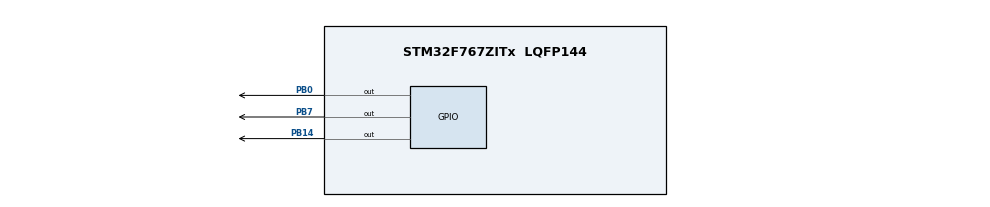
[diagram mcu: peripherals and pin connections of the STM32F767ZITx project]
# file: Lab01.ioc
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Mcu.Family=STM32F7
Mcu.Name=STM32F767ZITx
Mcu.Package=LQFP144
NVIC.PriorityGroup=NVIC_PRIORITYGROUP_4
PB0.Signal=GPIO_Output
PB14.Signal=GPIO_Output
PB7.Signal=GPIO_Output
ProjectManager.HeapSize=0x200
ProjectManager.StackSize=0x400
ProjectManager.TargetToolchain=STM32CubeIDE
RCC.HSE_VALUE=25000000
RCC.HSI_VALUE=16000000
RCC.LSE_VALUE=32768
RCC.USBFreq_Value=96000000
RCC.VCOOutputFreq_Value=192000000
board=custom

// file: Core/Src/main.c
/* USER CODE BEGIN Header */
/**
  ******************************************************************************
  * @file           : main.c
  * @brief          : Main program body
  ******************************************************************************
  * @attention
  *
  * Copyright (c) 2022 STMicroelectronics.
  * All rights reserved.
  *
  * This software is licensed under terms that can be found in the LICENSE file
  * in the root directory of this software component.
  * If no LICENSE file comes with this software, it is provided AS-IS.
  *
  ******************************************************************************
  */
/* USER CODE END Header */
#include "main.h"
#include "gpio.h"

/* USER CODE BEGIN PV */
uint8_t num = 0;
uint8_t led0 = 0;
uint8_t led1 = 0;
uint8_t led2 = 0;
/* USER CODE END PV */

void SystemClock_Config(void);

int main(void)
{

  /* MCU Configuration--------------------------------------------------------*/

  /* Reset of all peripherals, Initializes the Flash interface and the Systick. */
  HAL_Init();

  /* Configure the system clock */
  SystemClock_Config();

  /* Initialize all configured peripherals */
  MX_GPIO_Init();

  /* Infinite loop */
  while (1)
  {

    /* USER CODE BEGIN 3 */
	 LedCount3bit(0,0,0);
	 HAL_Delay(300);

	 LedCount3bit(0,0,1);
	 HAL_Delay(300);

	 LedCount3bit(0,1,0);
	 HAL_Delay(300);

	 LedCount3bit(0,1,1);
	 HAL_Delay(300);

	 LedCount3bit(1,0,0);
	 HAL_Delay(300);

	 LedCount3bit(1,0,1);
	 HAL_Delay(300);

	 LedCount3bit(1,1,0);
	 HAL_Delay(300);

	 LedCount3bit(1,1,1);
	 HAL_Delay(300);

	  num++;
	  if (num > 7)
		  num = 0;
  }
  /* USER CODE END 3 */
}

void LedCount3bit(uint8_t msb, uint8_t mid,uint8_t lsb)
{
		HAL_GPIO_WritePin(GPIOB, GPIO_PIN_14,led2 = msb);
		HAL_GPIO_WritePin(GPIOB, GPIO_PIN_7,led1 = mid);
		HAL_GPIO_WritePin(GPIOB, GPIO_PIN_0,led0 = lsb);

}
void SystemClock_Config(void)
{
  RCC_OscInitTypeDef RCC_OscInitStruct = {0};
  RCC_ClkInitTypeDef RCC_ClkInitStruct = {0};

  /** Configure the main internal regulator output voltage
  */
  __HAL_RCC_PWR_CLK_ENABLE();
  __HAL_PWR_VOLTAGESCALING_CONFIG(PWR_REGULATOR_VOLTAGE_SCALE3);

  /** Initializes the RCC Oscillators according to the specified parameters
  * in the RCC_OscInitTypeDef structure.
  */
  RCC_OscInitStruct.OscillatorType = RCC_OSCILLATORTYPE_HSI;
  RCC_OscInitStruct.HSIState = RCC_HSI_ON;
  RCC_OscInitStruct.HSICalibrationValue = RCC_HSICALIBRATION_DEFAULT;
  RCC_OscInitStruct.PLL.PLLState = RCC_PLL_NONE;
  if (HAL_RCC_OscConfig(&RCC_OscInitStruct) != HAL_OK)
  {
    Error_Handler();
  }

  /** Initializes the CPU, AHB and APB buses clocks
  */
  RCC_ClkInitStruct.ClockType = RCC_CLOCKTYPE_HCLK|RCC_CLOCKTYPE_SYSCLK
                              |RCC_CLOCKTYPE_PCLK1|RCC_CLOCKTYPE_PCLK2;
  RCC_ClkInitStruct.SYSCLKSource = RCC_SYSCLKSOURCE_HSI;
  RCC_ClkInitStruct.AHBCLKDivider = RCC_SYSCLK_DIV1;
  RCC_ClkInitStruct.APB1CLKDivider = RCC_HCLK_DIV1;
  RCC_ClkInitStruct.APB2CLKDivider = RCC_HCLK_DIV1;

  if (HAL_RCC_ClockConfig(&RCC_ClkInitStruct, FLASH_LATENCY_0) != HAL_OK)
  {
    Error_Handler();
  }
}

void Error_Handler(void)
{
  __disable_irq();
  while (1)
  {
  }
}
